# CC1101_Radio_Interface_1 register map
Vendor: Texas Instruments
Peripheral module from a debugger description file (folder msp430).
Registers are 16-bit, access not given, no defined reset value unless marked. A register's access mark holds for its fields unless they carry their own. Offsets are as the file gives them; lines under a group give offsets from that group; [hi:lo] are bit positions; {n}, {i} and the like mark numbered series; 'fields as' and 'values as' point back to an identical list; <NAME> marks a mode.

## CC1101_Radio_Interface
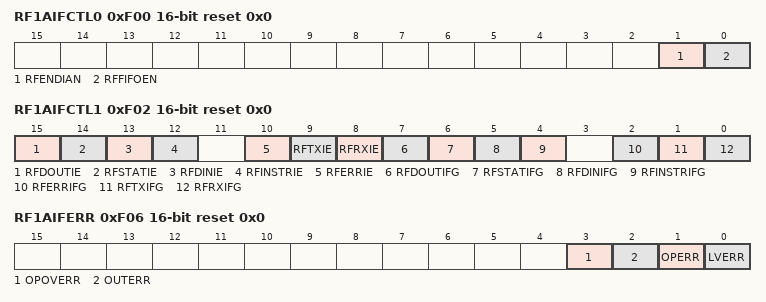
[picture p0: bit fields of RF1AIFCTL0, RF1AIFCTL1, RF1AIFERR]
0xF00 RF1AIFCTL0 rw reset 0x0 — Radio interface control register 0
  [1] RFENDIAN — CC1101 Disable endianness conversion
  [0] RFFIFOEN — CC1101 Direct FIFO access enable
0xF02 RF1AIFCTL1 rw reset 0x0 — Radio interface control register 1
  [15] RFDOUTIE — Radio interface data out interrupt enable
  [14] RFSTATIE — Radio interface status interrupt enable
  [13] RFDINIE — Radio interface data in interrupt enable
  [12] RFINSTRIE — Radio interface instruction interrupt enable
  [10] RFERRIE — Radio interface error interrupt enable
  [9] RFTXIE — Radio interface direct FIFO access transmit interrupt enable
  [8] RFRXIE — Radio interface direct FIFO access receive interrupt enable
  [7] RFDOUTIFG — Radio interface data out interrupt flag
  [6] RFSTATIFG — Radio interface status interrupt flag
  [5] RFDINIFG — Radio interface data in interrupt flag
  [4] RFINSTRIFG — Radio interface instruction interrupt flag
  [2] RFERRIFG — Radio interface error interrupt flag
  [1] RFTXIFG — Radio interface direct FIFO access transmit interrupt flag
  [0] RFRXIFG — Radio interface direct FIFO access receive interrupt flag
0xF04 RF1AIFCTL2 — (Radio interface control register 2)
0xF06 RF1AIFERR rw reset 0x0 — Radio interface error flag register
  [3] OPOVERR — Operand Overwrite Error Flag
  [2] OUTERR — Output data not available Error Flag
  [1] OPERR — Operand Error Flag
  [0] LVERR — Low Core Voltage Error Flag
0xF0C RF1AIFERRV — Radio interface error vector word register
0xF0E RF1AIFIV — Radio interface interrupt vector word register
0xF10 RF1AINSTRW — Radio instruction word register
0xF12 RF1AINSTR1W — Radio instruction 1-byte register with autoread
0xF14 RF1AINSTR2W — Radio instruction 2-byte register with autoread
0xF16 RF1ADINW — Radio word data in register
0xF20 RF1ASTAT0W — Radio status word register without auto-read
0xF22 RF1ASTAT1W — Radio status word register with 1-byte auto-read
0xF24 RF1ASTAT2W — Radio status word register with 2-byte auto-read
0xF28 RF1ADOUT0W — Radio core word data out register without auto-read
0xF2A RF1ADOUT1W — Radio core word data out register with 1-byte auto-read
0xF2C RF1ADOUT2W — Radio core word data out register with 2-byte auto-read
0xF30 RF1AIN — Radio core signal input register
0xF32 RF1AIFG — Radio core interrupt flag register
0xF34 RF1AIES — Radio core interrupt edge select register
0xF36 RF1AIE — Radio core interrupt enable register
0xF38 RF1AIV — Radio core interrupt vector word register
0xF3C RF1ARXFIFO — Direct receive FIFO access register
0xF3E RF1ATXFIFO — Direct transmit FIFO access register
